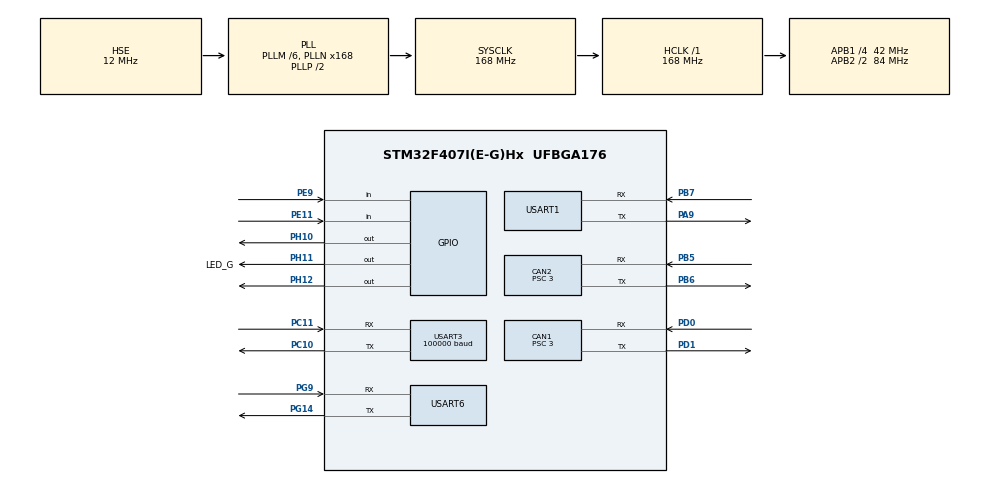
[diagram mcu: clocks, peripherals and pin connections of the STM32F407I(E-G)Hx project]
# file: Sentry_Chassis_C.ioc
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CAN1.BS1=CAN_BS1_10TQ
CAN1.BS2=CAN_BS2_3TQ
CAN1.CalculateBaudRate=1000000
CAN1.CalculateTimeBit=1000
CAN1.CalculateTimeQuantum=71.42857142857143
CAN1.Prescaler=3
CAN2.BS1=CAN_BS1_10TQ
CAN2.BS2=CAN_BS2_3TQ
CAN2.CalculateBaudRate=1000000
CAN2.CalculateTimeBit=1000
CAN2.CalculateTimeQuantum=71.42857142857143
CAN2.Prescaler=3
Dma.Request0=USART3_RX
Dma.Request1=USART6_RX
Dma.Request2=USART6_TX
Dma.Request3=USART1_RX
Dma.Request4=USART1_TX
Dma.USART1_RX.3.Direction=DMA_PERIPH_TO_MEMORY
Dma.USART1_RX.3.FIFOMode=DMA_FIFOMODE_DISABLE
Dma.USART1_RX.3.Instance=DMA2_Stream2
Dma.USART1_RX.3.MemDataAlignment=DMA_MDATAALIGN_BYTE
Dma.USART1_RX.3.MemInc=DMA_MINC_ENABLE
Dma.USART1_RX.3.Mode=DMA_NORMAL
Dma.USART1_RX.3.PeriphDataAlignment=DMA_PDATAALIGN_BYTE
Dma.USART1_RX.3.PeriphInc=DMA_PINC_DISABLE
Dma.USART1_RX.3.Priority=DMA_PRIORITY_LOW
Dma.USART1_TX.4.Direction=DMA_MEMORY_TO_PERIPH
Dma.USART1_TX.4.FIFOMode=DMA_FIFOMODE_DISABLE
Dma.USART1_TX.4.Instance=DMA2_Stream7
Dma.USART1_TX.4.MemDataAlignment=DMA_MDATAALIGN_BYTE
Dma.USART1_TX.4.MemInc=DMA_MINC_ENABLE
Dma.USART1_TX.4.Mode=DMA_NORMAL
Dma.USART1_TX.4.PeriphDataAlignment=DMA_PDATAALIGN_BYTE
Dma.USART1_TX.4.PeriphInc=DMA_PINC_DISABLE
Dma.USART1_TX.4.Priority=DMA_PRIORITY_LOW
Dma.USART3_RX.0.Direction=DMA_PERIPH_TO_MEMORY
Dma.USART3_RX.0.FIFOMode=DMA_FIFOMODE_DISABLE
Dma.USART3_RX.0.Instance=DMA1_Stream1
Dma.USART3_RX.0.MemDataAlignment=DMA_MDATAALIGN_BYTE
Dma.USART3_RX.0.MemInc=DMA_MINC_ENABLE
Dma.USART3_RX.0.Mode=DMA_NORMAL
Dma.USART3_RX.0.PeriphDataAlignment=DMA_PDATAALIGN_BYTE
Dma.USART3_RX.0.PeriphInc=DMA_PINC_DISABLE
Dma.USART3_RX.0.Priority=DMA_PRIORITY_VERY_HIGH
Dma.USART6_RX.1.Direction=DMA_PERIPH_TO_MEMORY
Dma.USART6_RX.1.FIFOMode=DMA_FIFOMODE_DISABLE
Dma.USART6_RX.1.Instance=DMA2_Stream1
Dma.USART6_RX.1.MemDataAlignment=DMA_MDATAALIGN_BYTE
Dma.USART6_RX.1.MemInc=DMA_MINC_ENABLE
Dma.USART6_RX.1.Mode=DMA_NORMAL
Dma.USART6_RX.1.PeriphDataAlignment=DMA_PDATAALIGN_BYTE
Dma.USART6_RX.1.PeriphInc=DMA_PINC_DISABLE
Dma.USART6_RX.1.Priority=DMA_PRIORITY_HIGH
Dma.USART6_TX.2.Direction=DMA_MEMORY_TO_PERIPH
Dma.USART6_TX.2.FIFOMode=DMA_FIFOMODE_DISABLE
Dma.USART6_TX.2.Instance=DMA2_Stream6
Dma.USART6_TX.2.MemDataAlignment=DMA_MDATAALIGN_BYTE
Dma.USART6_TX.2.MemInc=DMA_MINC_ENABLE
Dma.USART6_TX.2.Mode=DMA_NORMAL
Dma.USART6_TX.2.PeriphDataAlignment=DMA_PDATAALIGN_BYTE
Dma.USART6_TX.2.PeriphInc=DMA_PINC_DISABLE
Dma.USART6_TX.2.Priority=DMA_PRIORITY_HIGH
FREERTOS.Tasks01=Debug_Task,-3,128,Debug_Task_Start,As weak,NULL,Dynamic,NULL,NULL;Chassis_Task,0,1024,Chassis_Task_Start,As weak,NULL,Dynamic,NULL,NULL;Data_Tx_Task,1,512,Data_Tx_Task_Start,As weak,NULL,Dynamic,NULL,NULL;Referee_Task,0,258,Referee_Task_Start,As weak,NULL,Dynamic,NULL,NULL
Mcu.Family=STM32F4
Mcu.Name=STM32F407I(E-G)Hx
Mcu.Package=UFBGA176
NVIC.CAN1_RX0_IRQn=true\:5\:0\:false\:false\:true\:true\:true\:true\:true
NVIC.CAN2_RX1_IRQn=true\:5\:0\:false\:false\:true\:true\:true\:true\:true
NVIC.DMA1_Stream1_IRQn=true\:5\:0\:false\:false\:true\:true\:false\:true\:true
NVIC.DMA2_Stream1_IRQn=true\:5\:0\:false\:false\:true\:true\:false\:true\:true
NVIC.DMA2_Stream2_IRQn=true\:5\:0\:false\:false\:true\:true\:false\:true\:true
NVIC.DMA2_Stream6_IRQn=true\:5\:0\:false\:false\:true\:true\:false\:true\:true
NVIC.DMA2_Stream7_IRQn=true\:5\:0\:false\:false\:true\:true\:false\:true\:true
NVIC.PriorityGroup=NVIC_PRIORITYGROUP_4
NVIC.TIM1_UP_TIM10_IRQn=true\:15\:0\:false\:false\:true\:false\:false\:true\:true
NVIC.TIM8_TRG_COM_TIM14_IRQn=true\:5\:0\:false\:false\:true\:true\:true\:true\:true
NVIC.TIM8_UP_TIM13_IRQn=true\:5\:0\:false\:false\:true\:true\:true\:true\:true
NVIC.TimeBase=TIM1_UP_TIM10_IRQn
NVIC.TimeBaseIP=TIM1
NVIC.USART1_IRQn=true\:5\:0\:false\:false\:true\:true\:true\:true\:true
NVIC.USART3_IRQn=true\:5\:0\:false\:false\:true\:true\:true\:true\:true
NVIC.USART6_IRQn=true\:5\:0\:false\:false\:true\:true\:true\:true\:true
PA13.Mode=Serial_Wire
PA13.Signal=SYS_JTMS-SWDIO
PA14.Mode=Serial_Wire
PA14.Signal=SYS_JTCK-SWCLK
PA9.Mode=Asynchronous
PA9.Signal=USART1_TX
PB5.Mode=CAN_Activate
PB5.Signal=CAN2_RX
PB6.Mode=CAN_Activate
PB6.Signal=CAN2_TX
PB7.Mode=Asynchronous
PB7.Signal=USART1_RX
PC10.Mode=Asynchronous
PC10.Signal=USART3_TX
PC11.Mode=Asynchronous
PC11.Signal=USART3_RX
PD0.Mode=CAN_Activate
PD0.Signal=CAN1_RX
PD1.Mode=CAN_Activate
PD1.Signal=CAN1_TX
PE11.Signal=GPIO_Input
PE9.Signal=GPIO_Input
PG14.Mode=Asynchronous
PG14.Signal=USART6_TX
PG9.Mode=Asynchronous
PG9.Signal=USART6_RX
PH0-OSC_IN.Mode=HSE-External-Oscillator
PH0-OSC_IN.Signal=RCC_OSC_IN
PH1-OSC_OUT.Mode=HSE-External-Oscillator
PH1-OSC_OUT.Signal=RCC_OSC_OUT
PH10.Signal=GPIO_Output
PH11.GPIO_Label=LED_G
PH11.Signal=GPIO_Output
PH12.Signal=GPIO_Output
ProjectManager.HeapSize=0x2000
ProjectManager.StackSize=0x4000
ProjectManager.TargetToolchain=MDK-ARM V5.32
RCC.48MHZClocksFreq_Value=42000000
RCC.AHBFreq_Value=168000000
RCC.APB1CLKDivider=RCC_HCLK_DIV4
RCC.APB1Freq_Value=42000000
RCC.APB1TimFreq_Value=84000000
RCC.APB2CLKDivider=RCC_HCLK_DIV2
RCC.APB2Freq_Value=84000000
RCC.APB2TimFreq_Value=168000000
RCC.CortexFreq_Value=168000000
RCC.HCLKFreq_Value=168000000
RCC.HSE_VALUE=12000000
RCC.HSI_VALUE=16000000
RCC.LSE_VALUE=32768
RCC.PLLM=6
RCC.PLLN=168
RCC.PLLQ=8
RCC.PLLSourceVirtual=RCC_PLLSOURCE_HSE
RCC.SYSCLKFreq_VALUE=168000000
RCC.SYSCLKSource=RCC_SYSCLKSOURCE_PLLCLK
RCC.VCOOutputFreq_Value=336000000
TIM13.Period=9999
TIM13.Prescaler=83
TIM14.Period=999
TIM14.Prescaler=83
USART1.VirtualMode=VM_ASYNC
USART3.BaudRate=100000
USART3.Parity=PARITY_EVEN
USART3.VirtualMode=VM_ASYNC
USART6.VirtualMode=VM_ASYNC
VP_FREERTOS_VS_CMSIS_V1.Mode=CMSIS_V1
VP_RNG_VS_RNG.Mode=RNG_Activate
VP_SYS_VS_tim1.Mode=TIM1
VP_TIM13_VS_ClockSourceINT.Mode=Enable_Timer
VP_TIM14_VS_ClockSourceINT.Mode=Enable_Timer
board=custom

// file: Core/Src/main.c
/* USER CODE BEGIN Header */
/**
  ******************************************************************************
  * @file           : main.c
  * @brief          : Main program body
  ******************************************************************************
  * @attention
  *
  * Copyright (c) 2022 STMicroelectronics.
  * All rights reserved.
  *
  * This software is licensed under terms that can be found in the LICENSE file
  * in the root directory of this software component.
  * If no LICENSE file comes with this software, it is provided AS-IS.
  *
  ******************************************************************************
  */
/* USER CODE END Header */
#include "main.h"
#include "cmsis_os.h"
#include "can.h"
#include "dma.h"
#include "rng.h"
#include "tim.h"
#include "usart.h"
#include "gpio.h"

/* USER CODE BEGIN Includes */
#include "bsp_rc.h"
#include "bsp_timer.h"
#include "bsp_delay.h"
#include "bsp_can.h"
#include "rng.h"
#include "rand_num.h"
/* USER CODE END Includes */

void SystemClock_Config(void);
void MX_FREERTOS_Init(void);

int main(void)
 {

  /* MCU Configuration--------------------------------------------------------*/

  /* Reset of all peripherals, Initializes the Flash interface and the Systick. */
  HAL_Init();

  /* Configure the system clock */
  SystemClock_Config();

  /* Initialize all configured peripherals */
  MX_GPIO_Init();
  MX_DMA_Init();
  MX_CAN1_Init();
  MX_CAN2_Init();
  MX_TIM13_Init();
  MX_TIM14_Init();
  MX_USART1_UART_Init();
  MX_USART3_UART_Init();
  MX_USART6_UART_Init();
  MX_RNG_Init();
  /* USER CODE BEGIN 2 */
  delay_init();
  RNG_Init();
  remote_control_init();
  can_filter_init();
  Timer_Start();
  /* USER CODE END 2 */

  /* Call init function for freertos objects (in freertos.c) */
  MX_FREERTOS_Init();
  /* Start scheduler */
  osKernelStart();

  /* We should never get here as control is now taken by the scheduler */
  /* Infinite loop */
  while (1)
  {

  }
}

void SystemClock_Config(void)
{
  RCC_OscInitTypeDef RCC_OscInitStruct = {0};
  RCC_ClkInitTypeDef RCC_ClkInitStruct = {0};

  /** Configure the main internal regulator output voltage
  */
  __HAL_RCC_PWR_CLK_ENABLE();
  __HAL_PWR_VOLTAGESCALING_CONFIG(PWR_REGULATOR_VOLTAGE_SCALE1);
  /** Initializes the RCC Oscillators according to the specified parameters
  * in the RCC_OscInitTypeDef structure.
  */
  RCC_OscInitStruct.OscillatorType = RCC_OSCILLATORTYPE_HSE;
  RCC_OscInitStruct.HSEState = RCC_HSE_ON;
  RCC_OscInitStruct.PLL.PLLState = RCC_PLL_ON;
  RCC_OscInitStruct.PLL.PLLSource = RCC_PLLSOURCE_HSE;
  RCC_OscInitStruct.PLL.PLLM = 6;
  RCC_OscInitStruct.PLL.PLLN = 168;
  RCC_OscInitStruct.PLL.PLLP = RCC_PLLP_DIV2;
  RCC_OscInitStruct.PLL.PLLQ = 8;
  if (HAL_RCC_OscConfig(&RCC_OscInitStruct) != HAL_OK)
  {
    Error_Handler();
  }
  /** Initializes the CPU, AHB and APB buses clocks
  */
  RCC_ClkInitStruct.ClockType = RCC_CLOCKTYPE_HCLK|RCC_CLOCKTYPE_SYSCLK
                              |RCC_CLOCKTYPE_PCLK1|RCC_CLOCKTYPE_PCLK2;
  RCC_ClkInitStruct.SYSCLKSource = RCC_SYSCLKSOURCE_PLLCLK;
  RCC_ClkInitStruct.AHBCLKDivider = RCC_SYSCLK_DIV1;
  RCC_ClkInitStruct.APB1CLKDivider = RCC_HCLK_DIV4;
  RCC_ClkInitStruct.APB2CLKDivider = RCC_HCLK_DIV2;

  if (HAL_RCC_ClockConfig(&RCC_ClkInitStruct, FLASH_LATENCY_5) != HAL_OK)
  {
    Error_Handler();
  }
}

void Error_Handler(void)
{
  __disable_irq();
  while (1)
  {
  }
}

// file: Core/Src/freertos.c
/* USER CODE BEGIN Header */
/**
  ******************************************************************************
  * File Name          : freertos.c
  * Description        : Code for freertos applications
  ******************************************************************************
  * @attention
  *
  * Copyright (c) 2022 STMicroelectronics.
  * All rights reserved.
  *
  * This software is licensed under terms that can be found in the LICENSE file
  * in the root directory of this software component.
  * If no LICENSE file comes with this software, it is provided AS-IS.
  *
  ******************************************************************************
  */
/* USER CODE END Header */

#include "FreeRTOS.h"
#include "task.h"
#include "main.h"
#include "cmsis_os.h"

osThreadId Debug_TaskHandle;
osThreadId Chassis_TaskHandle;
osThreadId Data_Tx_TaskHandle;
osThreadId Referee_TaskHandle;

void Debug_Task_Start(void const * argument);
void Chassis_Task_Start(void const * argument);
void Data_Tx_Task_Start(void const * argument);
void Referee_Task_Start(void const * argument);

void MX_FREERTOS_Init(void); /* (MISRA C 2004 rule 8.1) */

/* GetIdleTaskMemory prototype (linked to static allocation support) */
void vApplicationGetIdleTaskMemory( StaticTask_t **ppxIdleTaskTCBBuffer, StackType_t **ppxIdleTaskStackBuffer, uint32_t *pulIdleTaskStackSize );

/* USER CODE BEGIN GET_IDLE_TASK_MEMORY */
static StaticTask_t xIdleTaskTCBBuffer;
static StackType_t xIdleStack[configMINIMAL_STACK_SIZE];

void vApplicationGetIdleTaskMemory( StaticTask_t **ppxIdleTaskTCBBuffer, StackType_t **ppxIdleTaskStackBuffer, uint32_t *pulIdleTaskStackSize )
{
  *ppxIdleTaskTCBBuffer = &xIdleTaskTCBBuffer;
  *ppxIdleTaskStackBuffer = &xIdleStack[0];
  *pulIdleTaskStackSize = configMINIMAL_STACK_SIZE;
  /* place for user code */
}
/* USER CODE END GET_IDLE_TASK_MEMORY */

void MX_FREERTOS_Init(void) {

  /* Create the thread(s) */
  /* definition and creation of Debug_Task */
  osThreadDef(Debug_Task, Debug_Task_Start, osPriorityIdle, 0, 128);
  Debug_TaskHandle = osThreadCreate(osThread(Debug_Task), NULL);

  /* definition and creation of Chassis_Task */
  osThreadDef(Chassis_Task, Chassis_Task_Start, osPriorityNormal, 0, 1024);
  Chassis_TaskHandle = osThreadCreate(osThread(Chassis_Task), NULL);

  /* definition and creation of Data_Tx_Task */
  osThreadDef(Data_Tx_Task, Data_Tx_Task_Start, osPriorityAboveNormal, 0, 512);
  Data_Tx_TaskHandle = osThreadCreate(osThread(Data_Tx_Task), NULL);

  /* definition and creation of Referee_Task */
  osThreadDef(Referee_Task, Referee_Task_Start, osPriorityNormal, 0, 258);
  Referee_TaskHandle = osThreadCreate(osThread(Referee_Task), NULL);

}

__weak void Debug_Task_Start(void const * argument)
{
  for(;;)
  {
    osDelay(1);
  }
}

__weak void Chassis_Task_Start(void const * argument)
{
  for(;;)
  {
    osDelay(1);
  }
}

__weak void Data_Tx_Task_Start(void const * argument)
{
  for(;;)
  {
    osDelay(1);
  }
}

__weak void Referee_Task_Start(void const * argument)
{
  for(;;)
  {
    osDelay(1);
  }
}
